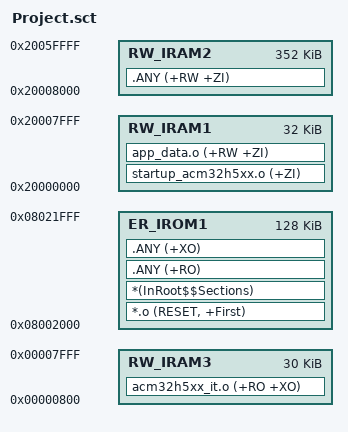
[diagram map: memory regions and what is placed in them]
; *************************************************************
; *** Scatter-Loading Description File generated by uVision ***
; *************************************************************

LR_IROM1 0x08002000 0x00020000  {    ; load region size_region
  ER_IROM1 0x08002000 0x00020000  {  ; load address = execution address
   *.o (RESET, +First)
   *(InRoot$$Sections)
   .ANY (+RO)
   .ANY (+XO)
  }
  RW_IRAM1 0x20000000 0x00008000  {  
    startup_acm32h5xx.o (+ZI)  ; Stack
    app_data.o (+RW +ZI)       ; RW-ZI Fast access data
  }
  RW_IRAM2 0x20008000 0x00058000  {
   .ANY (+RW +ZI)
  }
  RW_IRAM3 0x800 0x7800  {
   acm32h5xx_it.o (+RO +XO)
  }
}

